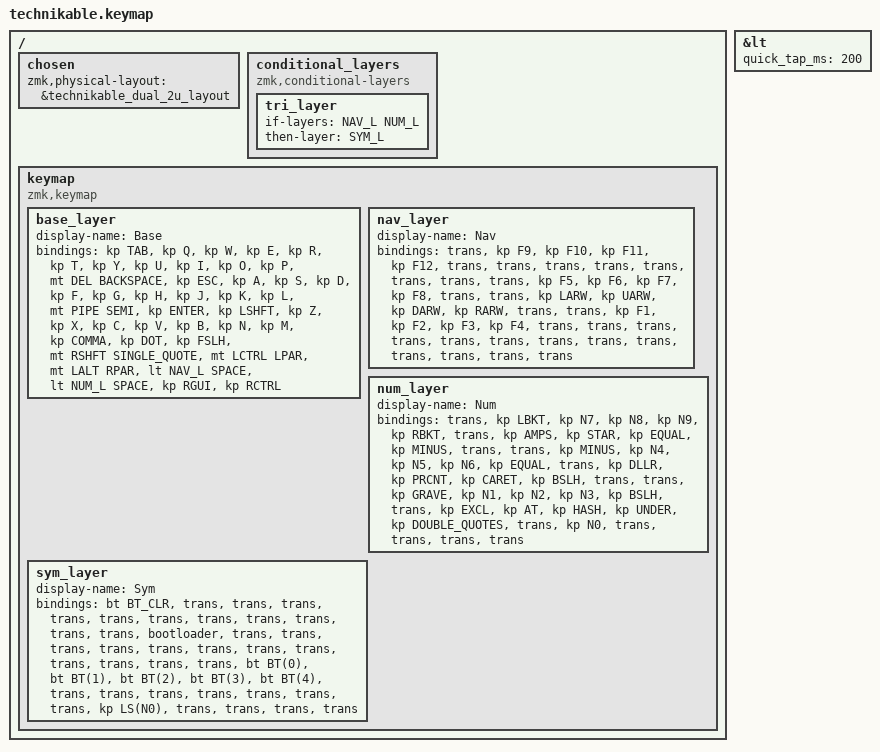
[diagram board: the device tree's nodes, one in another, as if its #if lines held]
/*
 * Copyright (c) 2022 Pete Johanson
 *
 * SPDX-License-Identifier: MIT
 */

#include <behaviors.dtsi>
#include <dt-bindings/zmk/keys.h>
#include <dt-bindings/zmk/bt.h>
#include <dt-bindings/zmk/outputs.h>

#define QWERTY_BASE 1

#define TBLE_ORTHO   true
// #define TBLE_MIT     true
// #define TBLE_DUAL_2U true

#define BAS_L 0
#define NAV_L 1
#define NUM_L 2
#define SYM_L 3

// Using layer taps on thumbs, having quick tap as well helps w/ repeating space/backspace
&lt { quick_tap_ms = <200>; };

#define BT(n) BT_SEL n

/ {
    chosen {
       zmk,physical-layout =
#ifdef TBLE_DUAL_2U
                       &technikable_dual_2u_layout;
#elif defined(TBLE_MIT)
                       &technikable_mit_layout;
#else
                       &technikable_ortho_layout;
#endif
    };

    conditional_layers {
        compatible = "zmk,conditional-layers";
	tri_layer {
	    if-layers = <NAV_L NUM_L>;
	    then-layer = <SYM_L>;
	};
    };

    keymap {
        compatible = "zmk,keymap";

        base_layer {
            display-name = "Base";
            bindings = <
#ifdef QWERTY_BASE
 &kp TAB    &kp Q      &kp W      &kp E       &kp R          &kp T          &kp Y            &kp U          &kp I       &kp O      &kp P         &mt DEL BACKSPACE
 &kp ESC    &kp A      &kp S      &kp D       &kp F          &kp G          &kp H            &kp J          &kp K       &kp L      &mt PIPE SEMI      &kp ENTER
 &kp LSHFT  &kp Z      &kp X      &kp C       &kp V          &kp B          &kp N            &kp M          &kp COMMA   &kp DOT    &kp FSLH      &mt RSHFT SINGLE_QUOTE
#else
 &kp TAB    &kp Q      &kp W      &kp F       &kp P          &kp B          &kp J            &kp L          &kp U       &kp Y      &kp QUOT     &mt DEL BACKSPACE
 &kp ESC    &kp A      &kp R      &kp S       &kp T          &kp G          &kp M            &kp N          &kp E       &kp I      &kp O        &kp ENTER
 &kp LSHFT  &kp Z      &kp X      &kp C       &kp D          &kp V          &kp K            &kp H          &kp COMMA   &kp DOT    &kp FSLH     &mt RSHFT SINGLE_QUOTE
#endif
#ifdef TBLE_DUAL_2U
                       &mt LCTRL LPAR  &mt LALT RPAR     &lt NAV_L SPACE                &lt NUM_L SPACE               &kp RGUI    &kp RCTRL
#elif defined(TBLE_MIT)
                       &mt LCTRL LPAR  &mt LALT RPAR    &mo NAV_L          &kp SPACE                   &mo NUM_L      &kp RGUI    &kp RCTRL
#else
                       &mt LCTRL LPAR  &mt LALT RPAR    &mo NAV_L      &kp SPACE      &kp SPACE        &mo NUM_L      &kp RGUI    &kp RCTRL
#endif
            >;
        };

        nav_layer {
            display-name = "Nav";
            bindings = <
&trans  &kp F9  &kp F10 &kp F11 &kp F12 &trans        &trans  &trans    &trans  &trans    &trans     &trans
&trans  &kp F5  &kp F6  &kp F7  &kp F8  &trans        &trans  &kp LARW  &kp UARW  &kp DARW  &kp RARW  &trans
&trans  &kp F1  &kp F2  &kp F3  &kp F4  &trans        &trans  &trans    &trans  &trans    &trans   &trans
#ifdef TBLE_DUAL_2U
                      &trans     &trans              &trans                    &trans       &trans         &trans
#elif defined(TBLE_MIT)
                      &trans     &trans      &trans                &trans             &trans      &trans   &trans
#else
                      &trans     &trans      &trans          &trans       &trans    &trans  &trans         &trans
#endif
            >;
        };

        num_layer {
            display-name = "Num";
            bindings = <
&trans      &kp LBKT   &kp N7    &kp N8  &kp N9    &kp RBKT     &trans      &kp AMPS  &kp STAR  &kp EQUAL  &kp MINUS  &trans
&trans      &kp MINUS  &kp N4    &kp N5  &kp N6    &kp EQUAL    &trans      &kp DLLR  &kp PRCNT &kp CARET  &kp BSLH   &trans
&trans      &kp GRAVE  &kp N1    &kp N2  &kp N3    &kp BSLH     &trans      &kp EXCL  &kp AT    &kp HASH   &kp UNDER  &kp DOUBLE_QUOTES
#ifdef TBLE_DUAL_2U
                     &trans     &kp N0              &trans                 &trans            &trans         &trans
#elif defined(TBLE_MIT)
                     &trans     &kp N0      &trans           &none            &kp ESC        &kp DEL      &trans
#else
                     &trans     &kp N0      &trans    &none         &none     &kp ESC        &kp DEL      &trans
#endif
            >;
        };

        sym_layer {
            display-name = "Sym";
            bindings = <
&bt BT_CLR     &trans     &trans     &trans      &trans          &trans       &trans     &trans       &trans    &trans   &trans   &trans
&bootloader    &trans     &trans     &trans      &trans          &trans       &trans     &trans       &trans    &trans   &trans   &trans
&trans         &bt BT(0)  &bt BT(1)  &bt BT(2)   &bt BT(3)       &bt BT(4)    &trans     &trans       &trans    &trans   &trans   &trans
#ifdef TBLE_DUAL_2U
                      &trans     &kp LS(N0)              &trans                    &trans       &trans         &trans
#elif defined(TBLE_MIT)
                      &trans     &kp LS(N0)      &trans                &trans             &trans      &trans   &trans
#else
                      &trans     &kp LS(N0)      &trans          &trans       &trans    &trans  &trans         &trans
#endif
            >;
        };

    };
};

